# facedancer register map
Vendor: luna-soc
Registers are 8-bit, read-write, reset 0x0 unless marked. A register's access mark holds for its fields unless they carry their own. Offsets are from the block's base; [hi:lo] are bit positions.

## usb0_ep_control
Base 0xF0000900
Same registers: usb1_ep_control 0xF0000D00, usb2_ep_control 0xF0001100
0x00 control — TODO amaranth_soc/csr/reg.py:471
  [7:0] address wo
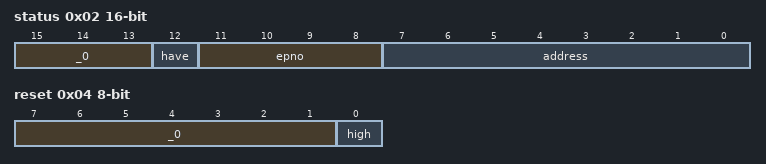
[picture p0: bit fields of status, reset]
0x02 status 16-bit — TODO amaranth_soc/csr/reg.py:471
  [15:13] _0 — TODO amaranth_soc/csr/reg.py:471
  [12] have ro — TODO amaranth_soc/csr/reg.py:471
  [11:8] epno ro — TODO amaranth_soc/csr/reg.py:471
  [7:0] address ro — TODO amaranth_soc/csr/reg.py:471
0x04 reset — TODO amaranth_soc/csr/reg.py:471
  [7:1] _0 — TODO amaranth_soc/csr/reg.py:471
  [0] high wo — TODO amaranth_soc/csr/reg.py:471
0x05 data — TODO amaranth_soc/csr/reg.py:471
  [7:0] byte ro
0x10 ev_enable — TODO amaranth_soc/csr/reg.py:471
  [0] mask
0x11 ev_pending — TODO amaranth_soc/csr/reg.py:471
  [0] mask

## usb0_ep_in
Base 0xF0000A00
Same registers: usb1_ep_in 0xF0000E00, usb2_ep_in 0xF0001200
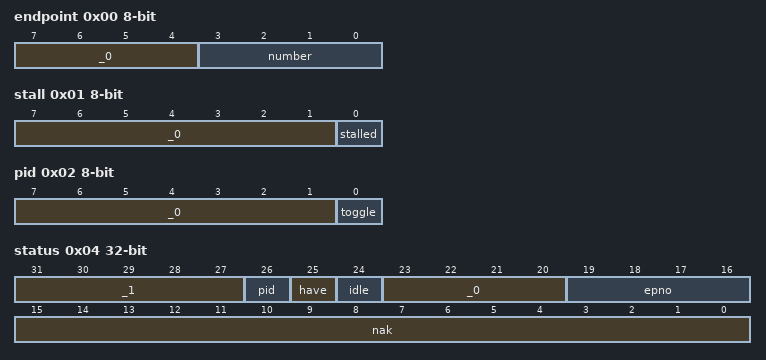
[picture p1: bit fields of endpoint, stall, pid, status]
0x00 endpoint — TODO amaranth_soc/csr/reg.py:471
  [7:4] _0 — TODO amaranth_soc/csr/reg.py:471
  [3:0] number wo — TODO amaranth_soc/csr/reg.py:471
0x01 stall — TODO amaranth_soc/csr/reg.py:471
  [7:1] _0 — TODO amaranth_soc/csr/reg.py:471
  [0] stalled wo — TODO amaranth_soc/csr/reg.py:471
0x02 pid — TODO amaranth_soc/csr/reg.py:471
  [7:1] _0 — TODO amaranth_soc/csr/reg.py:471
  [0] toggle wo — TODO amaranth_soc/csr/reg.py:471
0x04 status 32-bit — TODO amaranth_soc/csr/reg.py:471
  [31:27] _1 — TODO amaranth_soc/csr/reg.py:471
  [26] pid ro — TODO amaranth_soc/csr/reg.py:471
  [25] have ro — TODO amaranth_soc/csr/reg.py:471
  [24] idle ro — TODO amaranth_soc/csr/reg.py:471
  [23:20] _0 — TODO amaranth_soc/csr/reg.py:471
  [19:16] epno ro — TODO amaranth_soc/csr/reg.py:471
  [15:0] nak ro — TODO amaranth_soc/csr/reg.py:471
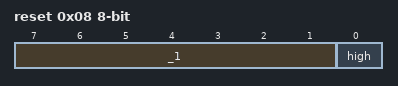
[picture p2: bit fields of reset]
0x08 reset — TODO amaranth_soc/csr/reg.py:471
  [7:1] _1 — TODO amaranth_soc/csr/reg.py:471
  [0] high wo — TODO amaranth_soc/csr/reg.py:471
0x09 data — TODO amaranth_soc/csr/reg.py:471
  [7:0] byte wo
0x10 ev_enable — TODO amaranth_soc/csr/reg.py:471
  [0] mask
0x11 ev_pending — TODO amaranth_soc/csr/reg.py:471
  [0] mask

## usb0_ep_out
Base 0xF0000B00
Same registers: usb1_ep_out 0xF0000F00, usb2_ep_out 0xF0001300
0x00 control — TODO amaranth_soc/csr/reg.py:471
  [7:0] address
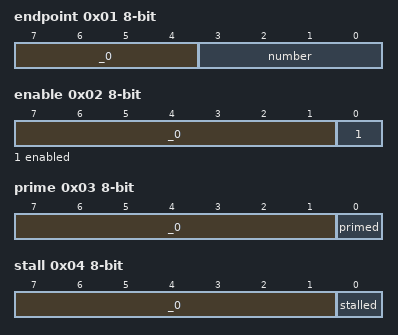
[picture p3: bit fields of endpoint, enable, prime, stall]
0x01 endpoint — TODO amaranth_soc/csr/reg.py:471
  [7:4] _0 — TODO amaranth_soc/csr/reg.py:471
  [3:0] number — TODO amaranth_soc/csr/reg.py:471
0x02 enable — TODO amaranth_soc/csr/reg.py:471
  [7:1] _0 — TODO amaranth_soc/csr/reg.py:471
  [0] enabled wo — TODO amaranth_soc/csr/reg.py:471
0x03 prime — TODO amaranth_soc/csr/reg.py:471
  [7:1] _0 — TODO amaranth_soc/csr/reg.py:471
  [0] primed wo — TODO amaranth_soc/csr/reg.py:471
0x04 stall — TODO amaranth_soc/csr/reg.py:471
  [7:1] _0 — TODO amaranth_soc/csr/reg.py:471
  [0] stalled wo — TODO amaranth_soc/csr/reg.py:471
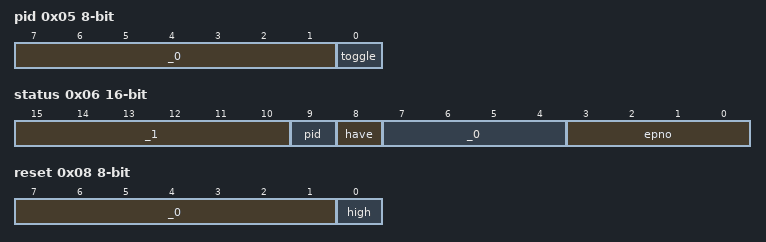
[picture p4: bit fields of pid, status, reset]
0x05 pid — TODO amaranth_soc/csr/reg.py:471
  [7:1] _0 — TODO amaranth_soc/csr/reg.py:471
  [0] toggle wo — TODO amaranth_soc/csr/reg.py:471
0x06 status 16-bit — TODO amaranth_soc/csr/reg.py:471
  [15:10] _1 — TODO amaranth_soc/csr/reg.py:471
  [9] pid ro — TODO amaranth_soc/csr/reg.py:471
  [8] have ro — TODO amaranth_soc/csr/reg.py:471
  [7:4] _0 — TODO amaranth_soc/csr/reg.py:471
  [3:0] epno ro — TODO amaranth_soc/csr/reg.py:471
0x08 reset — TODO amaranth_soc/csr/reg.py:471
  [7:1] _0 — TODO amaranth_soc/csr/reg.py:471
  [0] high wo — TODO amaranth_soc/csr/reg.py:471
0x09 data — TODO amaranth_soc/csr/reg.py:471
  [7:0] byte ro
0x20 ev_enable — TODO amaranth_soc/csr/reg.py:471
  [0] mask
0x21 ev_pending — TODO amaranth_soc/csr/reg.py:471
  [0] mask

## advertiser
Base 0xF0001400
0x00 control — TODO amaranth_soc/csr/reg.py:471
  [0] enable wo

## info
Base 0xF0001500
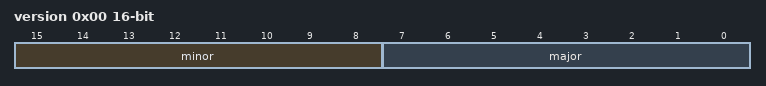
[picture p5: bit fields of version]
0x00 version 16-bit — TODO amaranth_soc/csr/reg.py:471
  [15:8] minor ro — TODO amaranth_soc/csr/reg.py:471
  [7:0] major ro — TODO amaranth_soc/csr/reg.py:471
